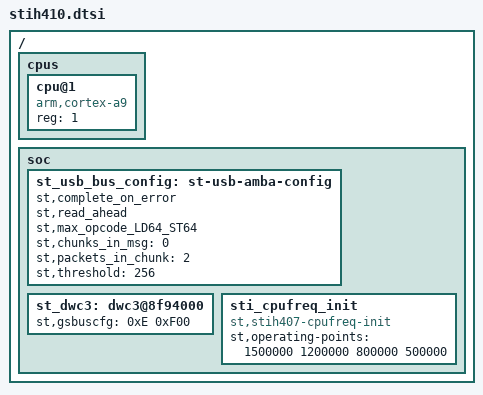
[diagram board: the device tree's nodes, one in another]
/*
 * Copyright (C) 2014 STMicroelectronics Limited.
 * Author: Giuseppe Cavallaro <peppe.cavallaro@st.com>
 *
 * This program is free software; you can redistribute it and/or modify
 * it under the terms of the GNU General Public License version 2 as
 * published by the Free Software Foundation.
 */
#include "stih410-clock.dtsi"
#include "stih407-family.dtsi"
/ {
	cpus {
		#address-cells = <1>;
		#size-cells = <0>;
		cpu@1 {
			device_type = "cpu";
			compatible = "arm,cortex-a9";
			reg = <1>;
		};
	};

	soc {
		st_usb_bus_config: st-usb-amba-config {
			st,complete_on_error;
			st,read_ahead;
			st,max_opcode_LD64_ST64;
			st,chunks_in_msg = <0>;
			st,packets_in_chunk = <2>;
			st,threshold = <256>;
		};

		st_dwc3: dwc3@8f94000 {
			st,gsbuscfg = <0xE 0xF00>;
		};

		sti_cpufreq_init {
			compatible = "st,stih407-cpufreq-init";
			st,operating-points = <
				/* kHz */
				1500000 1200000	800000 500000
			 >;
		};
	};
};
